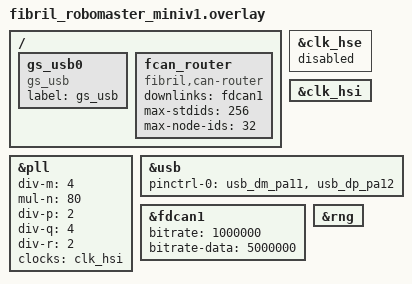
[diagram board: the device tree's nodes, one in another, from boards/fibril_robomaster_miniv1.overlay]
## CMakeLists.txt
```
# SPDX-License-Identifier: Apache-2.0
#
# Zephyr sample: fibril_can router + self node driven over CANnectivity's gs_usb
# uplink. Codegen produces the schema wrappers at build time from
# fibril_can_example/schema/example_node.yaml (same schema as example_node so
# the C service handlers and app_logic can be shared verbatim).
#
# Prerequisites: see the fibril_can module's zephyr/cmake/fcan_invoke_codegen.cmake
# for the fcan_codegen CLI resolution, and the message it prints if the binary
# is not on PATH.

cmake_minimum_required(VERSION 3.20.0)
find_package(Zephyr REQUIRED HINTS $ENV{ZEPHYR_BASE})

project(fibril_can_router_gs_usb_self LANGUAGES C)

if(NOT ZEPHYR_FIBRIL_CAN_MODULE_DIR)
  message(FATAL_ERROR
    "ZEPHYR_FIBRIL_CAN_MODULE_DIR is not set — is the fibril_can module on "
    "the west manifest and is CONFIG_FIBRIL_CAN=y?")
endif()

include(${ZEPHYR_FIBRIL_CAN_MODULE_DIR}/zephyr/cmake/fcan_invoke_codegen.cmake)

set(FCAN_EXAMPLE_SCHEMA
  "${ZEPHYR_FIBRIL_CAN_MODULE_DIR}/fibril_can_example/schema/example_node.yaml"
  CACHE FILEPATH "Schema YAML to feed into fcan_codegen")

fcan_invoke_codegen(
  SCHEMA     "${FCAN_EXAMPLE_SCHEMA}"
  OUTPUT_DIR "${CMAKE_CURRENT_BINARY_DIR}/schema_gen"
  BASE_NAME  schema_gen)

target_sources(app PRIVATE
  src/main.c
  src/app_logic.c
  src/rgb_state.c
  src/usbd_setup.c)

target_include_directories(app PRIVATE
  ${CMAKE_CURRENT_SOURCE_DIR}/src)
```

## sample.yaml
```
sample:
  name: fibril_can router + self node via CANnectivity gs_usb uplink
  description: >-
    Bring up a fibril_can slave whose typed wrappers are generated at build
    time by fcan_codegen from the shared example schema, embed it as the
    router's self node, and expose the router to a USB host through
    CANnectivity's gs_usb device class. A host on SocketCAN (or fibril_can_web
    over WebUSB) sees the self node's traffic combined with anything on the
    fdcan1 downlink through a single canX interface.

tests:
  sample.lib.fibril_can.router_gs_usb_self:
    tags:
      - fibril_can
      - can
      - router
      - usb
    # CONFIG_FIBRIL_CAN gates on the fibril_can module being on the west
    # manifest; the two dt_compat_enabled clauses gate on the board actually
    # wiring up both the router and a gs_usb node.
    filter: CONFIG_FIBRIL_CAN and dt_compat_enabled("fibril,can-router") and dt_compat_enabled("gs_usb")
    harness: console
    harness_config:
      type: multi_line
      ordered: true
      regex:
        - "router_gs_usb_self: fcan_init OK"
        - "router_gs_usb_self: fcan_router_attach_self OK"
        - "router_gs_usb_self: fcan_register_all OK"
        - "router_gs_usb_self: gs_usb_register OK"
        - "router_gs_usb_self: usbd_enable OK"
        - "router_gs_usb_self: entering main loop"
    integration_platforms:
      - fibril_robomaster_miniv1
    # Twister needs to know where fcan_codegen lives before it can build this
    # sample. Set FCAN_CODEGEN in the environment before invoking twister:
    #   FCAN_CODEGEN=/abs/path/fcan_codegen twister -T fibril_zephyr/samples/lib/fibril_can/router_gs_usb_self
    # or pass --extra-args=-DFCAN_CODEGEN=... to twister directly.
```

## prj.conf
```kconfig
# SPDX-License-Identifier: Apache-2.0

# --- fibril_can slave runtime + router driver
CONFIG_FIBRIL_CAN=y
CONFIG_CAN=y
CONFIG_CAN_FD_MODE=y
CONFIG_CAN_FCAN_ROUTER=y

# --- event-driven scheduler wake for fcan_zephyr_can_hal. This sample drives
#     fcan_poll(self) through the router thread (no fcan_zephyr_can_hal
#     instance), so the option has no runtime effect here; kept aligned with
#     the other fibril_can samples so the switch is uniform across the tree.
CONFIG_FCAN_ZEPHYR_EVENT_WAKE=y

# --- entropy for boot_id (used as ID-conflict tiebreaker + T_listen jitter
#     seed). Mini V1 has the on-chip RNG; overlay enables it.
CONFIG_ENTROPY_GENERATOR=y

# --- runtime allocation. K_HEAP_DEFINE in main.c carves its own arena, but
#     leave a small system heap for the CAN / USB / RNG drivers.
CONFIG_HEAP_MEM_POOL_SIZE=4096
CONFIG_MAIN_STACK_SIZE=4096

# --- USB device stack next + CANnectivity's gs_usb class. CONFIG_USBD_GS_USB
#     defaults to y whenever a "gs_usb" DT node is enabled, but state it
#     explicitly so the sample's intent is grep-able.
CONFIG_USB_DEVICE_STACK_NEXT=y
CONFIG_USBD_GS_USB=y

# Quieter USB stack -- switch the two lines below to _DBG when debugging USB
# enumeration failures on real hardware.
CONFIG_UDC_DRIVER_LOG_LEVEL_WRN=y
CONFIG_USBD_LOG_LEVEL_WRN=y
CONFIG_USBD_GS_USB_LOG_LEVEL_INF=y

# --- logging
CONFIG_LOG=y
CONFIG_LOG_MODE_IMMEDIATE=y
CONFIG_BOOT_BANNER=y
```

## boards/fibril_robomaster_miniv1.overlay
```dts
/*
 * SPDX-License-Identifier: Apache-2.0
 *
 * router+self+gs_usb sample on the Fibril RoboMaster Mini V1.
 *   uplink   = USB FS (PA11/PA12) -> gs_usb subsys -> fcan_router device
 *   downlink = FDCAN1 (PD0/PD1)   (board DTS already sets pinctrl + PLL_Q clock)
 *
 * The board's HSI48 + CLK48_SEL(0) supply the USB 48 MHz clock. This overlay
 * moves the PLL source from HSE (board DTS default) to HSI16 so the sample
 * boots on units where the 24 MHz HSE crystal is dead or unfitted -- the
 * Zephyr STM32 clock driver spin-waits for HSE ready and would hang boot
 * otherwise. HSI is ~1% accurate which is borderline for 5 Mbps FD data,
 * but adequate for bring-up. Switch back to HSE for production timing.
 */

/ {
	gs_usb0: gs_usb0 {
		compatible = "gs_usb";
		label = "gs_usb";
	};

	fcan_router: fcan_router {
		compatible = "fibril,can-router";
		status = "okay";
		downlinks = <&fdcan1>;
		max-stdids = <256>;
		max-node-ids = <32>;
	};
};

/* --- Clock tree: force HSI16 -> PLL, same VCO/SYSCLK/PLL_Q targets as the
 *     board's HSE path (VCO 320 MHz, SYSCLK 160 MHz, PLL_Q 80 MHz).
 *     HSI16 / div-m=4 = 4 MHz VCO input; * mul-n=80 = 320 MHz VCO;
 *     div-r=2 = 160 MHz SYSCLK; div-q=4 = 80 MHz PLL_Q. */
&clk_hse {
	status = "disabled";
};

&clk_hsi {
	status = "okay";
};

&pll {
	div-m = <4>;
	mul-n = <80>;
	div-p = <2>;
	div-q = <4>;
	div-r = <2>;
	clocks = <&clk_hsi>;
	status = "okay";
};

zephyr_udc0: &usb {
	pinctrl-0 = <&usb_dm_pa11 &usb_dp_pa12>;
	pinctrl-names = "default";
	status = "okay";
};

&fdcan1 {
	/* 1 Mbps arbitration / 5 Mbps FD data phase. PLL_Q kernel clock is 80 MHz
	 * per the board DTS -- 80 tq @ 1 Mbps, 16 tq @ 5 Mbps. */
	bitrate = <1000000>;
	bitrate-data = <5000000>;
	status = "okay";
};

&rng {
	status = "okay";
};
```

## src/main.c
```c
/*
 * SPDX-License-Identifier: Apache-2.0
 *
 * Zephyr entry point for the fibril_can router + self node + gs_usb sample.
 *
 * What the sample proves
 * ----------------------
 * 1. fcan_codegen'd wrappers link against the runtime on the Zephyr target.
 * 2. fcan_router (as a "fibril,can-router" Zephyr CAN device) hosts an
 *    embedded self node using fcan_router_get_self_hal()/
 *    fcan_router_attach_self() -- the three-step sequence documented in
 *    fibril_can/docs/09-router.md.
 * 3. The router device is registered as a gs_usb channel, so a host on USB
 *    sees a single CAN line that transparently combines the self node's
 *    traffic with any slaves attached to the fdcan1 downlink.
 * 4. fcan_router_poll() runs on the router driver thread and drives
 *    fcan_poll(self) internally, so the app main loop only has to publish
 *    telemetry and observe diagnostics.
 *
 * What the sample does NOT prove
 * ------------------------------
 * - Round-trip provisioning against fibril_can_bridge or fibril_can_web
 *   (needs a host process; see the README for the manual bring-up steps).
 * - Hardware timing on downlinks beyond what fdcan1's 1M/5M bitrate exercises
 *   in isolation.
 */

#include <stdint.h>
#include <string.h>

#include <zephyr/device.h>
#include <zephyr/drivers/can.h>
#include <zephyr/kernel.h>
#include <zephyr/logging/log.h>
#include <zephyr/random/random.h>

#include <cannectivity/usb/class/gs_usb.h>

#include <fibril_can/fcan.h>
#include <fibril_can/fcan_protocol.h>
#include <fibril_can/router/fcan_router.h>
#include <fibril_can_zephyr/can_router.h>

#include "schema_gen.h"
#include "app_logic.h"
#include "rgb_state.h"
#include "usbd_setup.h"

/* The C emitter puts these symbols in schema_blob.c but doesn't declare them
 * in schema_gen.h -- the C example does the same manual extern block. */
extern const uint8_t  fcan_schema_blob[];
extern const size_t   fcan_schema_blob_len;
extern const uint64_t fcan_schema_hash;

LOG_MODULE_REGISTER(router_gs_usb_self, LOG_LEVEL_INF);

#define ROUTER_NODE    DT_NODELABEL(fcan_router)
#define ROUTER_DEV     DEVICE_DT_GET(ROUTER_NODE)

/* Default 0x10 matches the fibril_can example schema's assumed slave ID; the
 * host bridge picks this up during ANNOUNCE. Override at build time with
 * -DCONFIG_EXTRA_CFLAGS=-DNODE_ID=0x?? if you need to run more than one of
 * these boards on the same bus. */
#ifndef NODE_ID
#define NODE_ID        0x10
#endif
#define MASTER_LOST_US 300000U  /* SPEC §5.11 -- 300 ms watchdog */

/* fcan_init calls the allocator once to carve every variable-length buffer
 * the runtime needs. Same 16 KiB budget as the example_node sample; the extra
 * headroom absorbs future schema growth without a re-tune. */
K_HEAP_DEFINE(fcan_heap, 16 * 1024);

static void *heap_alloc(size_t size, size_t align, void *ctx)
{
	ARG_UNUSED(ctx);
	return k_heap_aligned_alloc(&fcan_heap, align, size, K_NO_WAIT);
}

static const char *state_str(fcan_node_state_t s)
{
	switch (s) {
	case FCAN_STATE_UNPROVISIONED: return "UNPROVISIONED";
	case FCAN_STATE_PROVISIONED:   return "PROVISIONED";
	case FCAN_STATE_RUNNING:       return "RUNNING";
	case FCAN_STATE_FAULT:         return "FAULT";
	default:                       return "?";
	}
}

int main(void)
{
	const struct device *router = ROUTER_DEV;
	const struct device *gs_usb = DEVICE_DT_GET(DT_NODELABEL(gs_usb0));

	if (!device_is_ready(router)) {
		LOG_ERR("router device %s not ready", router->name);
		return -ENODEV;
	}

	fcan_router_t *r = fcan_router_zephyr_get(router);
	if (r == NULL) {
		LOG_ERR("fcan_router_zephyr_get returned NULL (router init failed)");
		return -ENODEV;
	}

	/* fcan_node_storage_size() is a runtime function (returns
	 * sizeof(fcan_node_t) -- opaque on purpose), so we heap-allocate the
	 * node instead of trying to size a static array. 8-byte alignment
	 * satisfies the seqlock and u64-hash fields the runtime keeps inside. */
	fcan_node_t *self = k_heap_aligned_alloc(&fcan_heap, 8,
						 fcan_node_storage_size(),
						 K_NO_WAIT);
	if (self == NULL) {
		LOG_ERR("fcan_heap OOM allocating node (%u bytes)",
			(unsigned)fcan_node_storage_size());
		return -ENOMEM;
	}

	/* MotorDriver has max_count=4 in the schema; ship 1 instance to keep
	 * the RAM footprint small. Imu is fixed count=1. */
	static const uint8_t counts[] = {1U, 1U};
	BUILD_ASSERT(ARRAY_SIZE(counts) == FCAN_NUM_BLOCK_ARRAYS,
		     "counts[] must match the schema's block-array count");

	fcan_config_t cfg = {
		.node_id = NODE_ID,
		.boot_id = sys_rand32_get(),
		.schema_blob = fcan_schema_blob,
		.schema_blob_len = (uint16_t)fcan_schema_blob_len,
		.schema_hash = fcan_schema_hash,
		.protocol_version = FCAN_PROTOCOL_VERSION,
		.block_count = FCAN_NUM_BLOCK_ARRAYS,
		.instance_counts = counts,
		.limits = {
			.max_frames = FCAN_MAX_FRAMES,
			.max_copy_entries = FCAN_MAX_COPY_ENTRIES,
			.service_buffer = FCAN_SERVICE_BUFFER,
			.service_reassembly = FCAN_SERVICE_REASSEMBLY,
			/* capacity fields filled below */
		},
		/* HAL comes from the router, not from a can_hal wrapper around
		 * a physical Zephyr CAN device: the router internally proxies
		 * this HAL onto its uplink, and the router thread drives
		 * fcan_poll(self) via fcan_router_poll(). */
		.hal = fcan_router_get_self_hal(r),
		.allocator = {.alloc = heap_alloc, .ctx = NULL},
		.master_lost_us = MASTER_LOST_US,
		/* .t_listen_us = 0 -> runtime picks the safe default. */
	};
	fcan_apply_schema_capacities(&cfg.limits, counts);

	if (fcan_init(self, &cfg) != FCAN_OK) {
		LOG_ERR("fcan_init failed (fault=%d)", (int)fcan_fault(self));
		return -EIO;
	}
	LOG_INF("fcan_init OK: node_id=0x%02x schema_hash=0x%016llx blob_len=%u",
		cfg.node_id, (unsigned long long)fcan_schema_hash,
		(unsigned)fcan_schema_blob_len);

	/* Attach BEFORE the router device is started (i.e. before the host can
	 * open the gs_usb channel). fcan_router_attach_self mutates state the
	 * router thread reads; docs/09-router.md documents this ordering. */
	if (fcan_router_attach_self(r, self) != FCAN_OK) {
		LOG_ERR("fcan_router_attach_self failed (fault=%d)",
			(int)fcan_fault(self));
		return -EIO;
	}
	LOG_INF("fcan_router_attach_self OK");

	if (fcan_register_all(self) != FCAN_OK) {
		LOG_ERR("fcan_register_all failed (fault=%d)",
			(int)fcan_fault(self));
		return -EIO;
	}
	LOG_INF("fcan_register_all OK");

	app_logic_init();
	rgb_state_init();

	if (!device_is_ready(gs_usb)) {
		LOG_ERR("gs_usb device %s not ready", gs_usb->name);
		return -ENODEV;
	}

	int rc = usbd_setup_init();
	if (rc != 0) {
		LOG_ERR("usbd_setup_init failed (%d)", rc);
		return rc;
	}

	const struct device *channels[] = {router};
	rc = gs_usb_register(gs_usb, channels, ARRAY_SIZE(channels), NULL, NULL);
	if (rc != 0) {
		LOG_ERR("gs_usb_register failed (%d)", rc);
		return rc;
	}
	LOG_INF("gs_usb_register OK (1 channel: %s)", router->name);

	rc = usbd_setup_enable();
	if (rc != 0) {
		return rc;
	}
	LOG_INF("usbd_enable OK");

	LOG_INF("entering main loop (tick=1 ms, state=%s)",
		state_str(fcan_state(self)));

	fcan_node_state_t last_state = fcan_state(self);
	uint32_t last_log_ms = 0;
	uint32_t last_led_ms = 0;
	while (true) {
		/* Threading model: fcan_poll(self) runs on the router driver
		 * thread (fcan_router_poll drives it at the end of each pass),
		 * so this main-thread app_logic_tick() must only use fcan APIs
		 * that are documented cross-thread-safe -- topic begin/commit/
		 * read and param_read are seqlock-protected per fcan_seqlock.h.
		 * Do NOT call fcan_svc_complete from here: it races the router
		 * thread's fcan_service_poll on the reassembly slots.
		 * app_logic.c completes the `home` service synchronously to
		 * keep that invariant, at the cost of skipping the ACCEPTED
		 * demo the example_node sample carries. */
		app_logic_tick(0.001f);

		const fcan_node_state_t s = fcan_state(self);
		if (s != last_state) {
			LOG_INF("state: %s -> %s (fault=%d)",
				state_str(last_state), state_str(s),
				(int)fcan_fault(self));
			last_state = s;
		}

		/* LED indicator @ ~100 Hz. GPIO toggles at every 1 ms tick would
		 * be wasteful; the blink phase is derived from k_uptime so a
		 * coarser refresh does not slur the animation. */
		const uint32_t now_ms = k_uptime_get_32();
		if ((now_ms - last_led_ms) >= 10U) {
			rgb_state_update(s, fcan_fault(self));
			last_led_ms = now_ms;
		}

		/* Router-oriented heartbeat log. fcan_router_get_diag() covers
		 * both forwarding directions and every drop reason; we surface
		 * the summary counters the operator needs to spot an
		 * ingress-drop condition or a runaway downlink. */
		if ((now_ms - last_log_ms) >= 1000U) {
			fcan_router_diag_t d;
			fcan_router_get_diag(r, &d);
			uint32_t ing_drops = fcan_router_zephyr_ingress_drops(router);
			LOG_INF("alive: state=%s up->dn[0]=%u dn->up[0]=%u "
				"drop_send=%u ingress_drops=%u",
				state_str(s),
				d.fwd_up_to_down[0], d.fwd_down_to_up[0],
				d.drop_send_failed, ing_drops);
			last_log_ms = now_ms;
		}

		k_msleep(1);
	}
	/* unreachable */
}
```

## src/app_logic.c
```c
/*
 * SPDX-License-Identifier: Apache-2.0
 *
 * Minimal toy application on top of the codegen wrappers. One MotorDriver
 * instance (motor0) integrates a 1-D dynamics model driven by the last M2S
 * `command` frame, publishes S2M `state` every tick and `diagnostics` at
 * ~10 Hz. One IMU instance publishes constant gyro/accel samples so the
 * S2M path is exercised for both block types.
 *
 * Divergence from example_node/src/app_logic.c
 * --------------------------------------------
 * Unlike example_node -- which runs fcan_poll and app_logic_tick on the same
 * main thread -- the router+self topology puts fcan_poll(self) on the router
 * driver thread (via fcan_router_poll) while app_logic_tick() runs on main.
 * Topic begin/commit/read and param_read stay safe across that boundary via
 * fcan_seqlock.h. fcan_svc_complete() does NOT: it races the router thread's
 * fcan_service_poll on the reassembly slots. So the `home` service handler
 * completes synchronously here (returns FCAN_SVC_OK with a filled response)
 * instead of stashing a handle for a later motordriver_home_complete call.
 * The deferred-response path is still demonstrated by the example_node sample.
 */

#include "app_logic.h"

#include <stdbool.h>
#include <stdint.h>

#include <zephyr/logging/log.h>

#include <fibril_can/fcan.h>
#include <fibril_can/fcan_protocol.h>

#include "schema_gen.h"

LOG_MODULE_REGISTER(fcan_app, LOG_LEVEL_INF);

#define MOTOR_INST      0U
#define IMU_INST        0U
#define DIAG_DIVIDER    100U  /* diagnostics @ 10 Hz when tick=1 kHz */

struct axis_state {
	float velocity;
	float position;
	float last_setpoint;
	uint8_t latched_mode;
	uint32_t fault_code;
	bool braked;
	uint32_t uptime_ticks;
};

static struct axis_state g_axis;

void app_logic_init(void)
{
	g_axis = (struct axis_state){0};
}

void app_logic_tick(float dt_seconds)
{
	/* 1. Absorb any queued master commands. */
	motordriver_command_t cmd;
	if (motordriver_command_read(MOTOR_INST, &cmd)) {
		g_axis.last_setpoint = cmd.setpoint;
		g_axis.latched_mode = cmd.mode;
	}
	motordriver_brake_t brk;
	if (motordriver_brake_read(MOTOR_INST, &brk)) {
		g_axis.braked = brk.engaged;
	}

	/* 2. Toy dynamics. Params are master-owned; we only read them. */
	const float kp = motordriver_param_kp(MOTOR_INST);
	const float torque_constant = motordriver_param_torque_constant(MOTOR_INST);
	const float drive = g_axis.braked ? 0.0f : kp * g_axis.last_setpoint;
	g_axis.velocity += drive * dt_seconds;
	g_axis.position += g_axis.velocity * dt_seconds;

	/* 3. High-rate telemetry. */
	motordriver_state_t *state = motordriver_state_begin(MOTOR_INST);
	if (state != NULL) {
		state->velocity = g_axis.velocity;
		state->position = g_axis.position;
		state->current = (torque_constant > 0.0f) ? drive / torque_constant : 0.0f;
		state->torque = drive;
		state->output_voltage = drive;
		state->bus_voltage = 24.0f;
		state->temperature = 25.0f;
		state->error_flags = g_axis.fault_code;
		motordriver_state_commit(MOTOR_INST);
	}

	/* 4. Low-rate diagnostics. No deferred-response completion here (see the
	 *    file header): motordriver_home returns synchronously in this sample
	 *    so nothing needs to complete a stashed handle from the app thread. */
	g_axis.uptime_ticks++;
	if ((g_axis.uptime_ticks % DIAG_DIVIDER) == 0U) {
		motordriver_diagnostics_t *diag = motordriver_diagnostics_begin(MOTOR_INST);
		if (diag != NULL) {
			diag->fault_code = g_axis.fault_code;
			diag->uptime_s = (uint32_t)((float)g_axis.uptime_ticks * dt_seconds);
			diag->mcu_temperature = 30.0f;
			diag->mode = g_axis.latched_mode;
			motordriver_diagnostics_commit(MOTOR_INST);
		}
	}

	/* 5. Constant IMU sample so the Imu S2M path is not dead code. */
	imu_sample_t *imu = imu_sample_begin(IMU_INST);
	if (imu != NULL) {
		imu->gyro[0] = 0.0f;
		imu->gyro[1] = 0.0f;
		imu->gyro[2] = 0.0f;
		imu->accel[0] = 0.0f;
		imu->accel[1] = 0.0f;
		imu->accel[2] = 9.81f;
		imu_sample_commit(IMU_INST);
	}
}

/* ---- Service handlers. codegen emits a dispatcher that calls each of these
 *      by symbol; any omission is a hard link error. See
 *      fibril_can_example/src/app_logic.cpp for the reference implementations. */

fcan_svc_status_t motordriver_set_mode(uint8_t inst,
				       const motordriver_set_mode_req_t *req,
				       motordriver_set_mode_resp_t *resp,
				       fcan_call_handle_t h)
{
	ARG_UNUSED(h);
	if (inst == MOTOR_INST) {
		g_axis.latched_mode = req->mode;
	}
	resp->accepted = true;
	return FCAN_SVC_OK;
}

fcan_svc_status_t motordriver_set_pid(uint8_t inst,
				      const motordriver_set_pid_req_t *req,
				      motordriver_set_pid_resp_t *resp,
				      fcan_call_handle_t h)
{
	ARG_UNUSED(inst);
	ARG_UNUSED(req);
	ARG_UNUSED(h);
	/* Canonical PID gain updates flow through PARAM_SET (§8). This handler
	 * exists so the schema's service surface is complete but does not
	 * touch the working values. */
	resp->accepted = true;
	return FCAN_SVC_OK;
}

fcan_svc_status_t motordriver_calibrate(uint8_t inst,
					const motordriver_calibrate_req_t *req,
					motordriver_calibrate_resp_t *resp,
					fcan_call_handle_t h)
{
	ARG_UNUSED(req);
	ARG_UNUSED(h);
	resp->offset = (inst == MOTOR_INST) ? g_axis.position : 0.0f;
	return FCAN_SVC_OK;
}

fcan_svc_status_t motordriver_clear_faults(uint8_t inst,
					   const motordriver_clear_faults_req_t *req,
					   motordriver_clear_faults_resp_t *resp,
					   fcan_call_handle_t h)
{
	ARG_UNUSED(req);
	ARG_UNUSED(h);
	if (inst == MOTOR_INST) {
		g_axis.fault_code = 0;
	}
	resp->success = true;
	return FCAN_SVC_OK;
}

fcan_svc_status_t motordriver_home(uint8_t inst,
				   const motordriver_home_req_t *req,
				   motordriver_home_resp_t *resp,
				   fcan_call_handle_t h)
{
	ARG_UNUSED(req);
	ARG_UNUSED(h);
	if (inst == MOTOR_INST) {
		g_axis.position = 0.0f;
		g_axis.velocity = 0.0f;
	}
	/* Synchronous completion: fill the response and return OK so the runtime
	 * sends it from this call's context (router driver thread). The
	 * deferred-response path (FCAN_SVC_ACCEPTED + motordriver_home_complete
	 * later) would trip on the router-thread vs app-thread race documented at
	 * the top of this file. */
	resp->success = true;
	return FCAN_SVC_OK;
}

void motordriver_on_params_changed(uint8_t inst, uint32_t changed_mask)
{
	LOG_INF("PARAM_SET applied: inst=%u mask=0x%08x kp=%f",
		inst, changed_mask, (double)motordriver_param_kp(inst));
}
```

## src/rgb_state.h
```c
/*
 * SPDX-License-Identifier: Apache-2.0
 *
 * Optional visual state indicator for the fibril_can example_node. Maps the
 * fcan_node runtime state (and fault code) onto the board's on-board LEDs so
 * a technician can see what the slave is doing without wiring up a serial
 * console.
 *
 * Boards that expose `led_r`, `led_g`, `led_b` gpio-leds children (currently:
 * fibril_robomaster_miniv1) drive the indicator. Boards that don't -- notably
 * native_sim -- fall back to a no-op implementation so the sample keeps
 * building unchanged.
 */

#ifndef FCAN_EXAMPLE_RGB_STATE_H_
#define FCAN_EXAMPLE_RGB_STATE_H_

#include <fibril_can/fcan_protocol.h>

#ifdef __cplusplus
extern "C" {
#endif

/* Configure the R/G/B outputs and drive them low (all off). Idempotent; safe
 * to call before the runtime is initialised. On boards without the three LED
 * nodes this is a no-op. */
void rgb_state_init(void);

/* Refresh the LED output for the given fcan runtime snapshot. Intended to be
 * called from the main loop at 100 Hz-ish; the internal blink phase is driven
 * from k_uptime_get_32() so callers do not need to keep any state.
 *
 * Priority: any non-NONE fault turns red on regardless of state. Otherwise:
 *   UNPROVISIONED -> blue, blinking at 1 Hz (500 ms on, 500 ms off)
 *   PROVISIONED   -> blue, solid
 *   RUNNING       -> green, solid
 *   FAULT         -> red, solid   (also reached via the fault-code branch)
 */
void rgb_state_update(fcan_node_state_t state, fcan_fault_t fault);

#ifdef __cplusplus
}
#endif

#endif /* FCAN_EXAMPLE_RGB_STATE_H_ */
```

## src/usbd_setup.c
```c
/*
 * SPDX-License-Identifier: Apache-2.0
 *
 * Minimal usbd_next boilerplate for the router+self+gs_usb sample.
 *
 * Compared to CANnectivity's app/src/usb.c this drops:
 *   - HS configuration      (Mini V1 is USB FS only)
 *   - DFU descriptors + switch-to-DFU flow
 *   - BOS + MSOSV2 platform capability (Windows WinUSB auto-bind)
 *
 * The registered class instance name matches gs_usb.c's USBD_DEFINE_CLASS
 * naming: the single "gs_usb" DT node lands at index 0 -> "gs_usb_0".
 */

#include "usbd_setup.h"

#include <zephyr/logging/log.h>
#include <zephyr/usb/usbd.h>

LOG_MODULE_REGISTER(usbd_setup, LOG_LEVEL_INF);

#define GS_USB_CLASS_INSTANCE_NAME "gs_usb_0"

/* Values match the CANnectivity firmware defaults so host-side udev rules and
 * gs_usb pid filters that already work with CANnectivity dongles work here
 * too. 0x1209 is pid.codes, 0xca01 is the block CANnectivity reserved for
 * gs_usb devices. Copy these values, don't include cannectivity's Kconfig --
 * that Kconfig only exists when its app is on the build. */
#define ROUTER_GS_USB_SELF_VID          0x1209U
#define ROUTER_GS_USB_SELF_PID          0xca01U
#define ROUTER_GS_USB_SELF_MANUFACTURER "CANnectivity"
#define ROUTER_GS_USB_SELF_PRODUCT      "CANnectivity USB to CAN adapter"
#define ROUTER_GS_USB_SELF_MAX_POWER    125U /* 250 mA (bMaxPower is in 2 mA units) */

USBD_DEVICE_DEFINE(usbd, DEVICE_DT_GET(DT_NODELABEL(zephyr_udc0)),
		   ROUTER_GS_USB_SELF_VID, ROUTER_GS_USB_SELF_PID);

USBD_DESC_LANG_DEFINE(lang);
USBD_DESC_MANUFACTURER_DEFINE(mfr, ROUTER_GS_USB_SELF_MANUFACTURER);
USBD_DESC_PRODUCT_DEFINE(product, ROUTER_GS_USB_SELF_PRODUCT);
USBD_DESC_SERIAL_NUMBER_DEFINE(sn);
USBD_DESC_CONFIG_DEFINE(fs_config_desc, "Full-Speed Configuration");

USBD_CONFIGURATION_DEFINE(fs_config, USB_SCD_SELF_POWERED,
			  ROUTER_GS_USB_SELF_MAX_POWER, &fs_config_desc);

int usbd_setup_init(void)
{
	int err;

	err = usbd_add_descriptor(&usbd, &lang);
	if (err != 0) {
		LOG_ERR("usbd_add_descriptor(lang) failed (%d)", err);
		return err;
	}

	err = usbd_add_descriptor(&usbd, &mfr);
	if (err != 0) {
		LOG_ERR("usbd_add_descriptor(mfr) failed (%d)", err);
		return err;
	}

	err = usbd_add_descriptor(&usbd, &product);
	if (err != 0) {
		LOG_ERR("usbd_add_descriptor(product) failed (%d)", err);
		return err;
	}

	err = usbd_add_descriptor(&usbd, &sn);
	if (err != 0) {
		LOG_ERR("usbd_add_descriptor(sn) failed (%d)", err);
		return err;
	}

	err = usbd_add_configuration(&usbd, USBD_SPEED_FS, &fs_config);
	if (err != 0) {
		LOG_ERR("usbd_add_configuration(fs) failed (%d)", err);
		return err;
	}

	err = usbd_register_class(&usbd, GS_USB_CLASS_INSTANCE_NAME,
				  USBD_SPEED_FS, 1);
	if (err != 0) {
		LOG_ERR("usbd_register_class(gs_usb_0) failed (%d)", err);
		return err;
	}

	err = usbd_device_set_code_triple(&usbd, USBD_SPEED_FS, 0, 0, 0);
	if (err != 0) {
		LOG_ERR("usbd_device_set_code_triple(fs) failed (%d)", err);
		return err;
	}

	err = usbd_device_set_bcd_usb(&usbd, USBD_SPEED_FS, USB_SRN_2_0_1);
	if (err != 0) {
		LOG_ERR("usbd_device_set_bcd_usb(fs) failed (%d)", err);
		return err;
	}

	err = usbd_init(&usbd);
	if (err != 0) {
		LOG_ERR("usbd_init failed (%d)", err);
		return err;
	}

	return 0;
}

int usbd_setup_enable(void)
{
	int err = usbd_enable(&usbd);

	if (err != 0) {
		LOG_ERR("usbd_enable failed (%d)", err);
	}
	return err;
}
```

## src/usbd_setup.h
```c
/*
 * SPDX-License-Identifier: Apache-2.0
 *
 * Minimal usbd_next boilerplate for the router+self+gs_usb sample. This is a
 * cut-down of CANnectivity's app/src/usb.c: full-speed only, no DFU, no
 * MSOSV2 descriptor set, no LED / termination / timestamp glue. The registered
 * gs_usb class instance ("gs_usb_0") is the same one CANnectivity registers.
 *
 * VID/PID/manufacturer/product strings are taken from the CANNECTIVITY_USB_*
 * Kconfig defaults so the resulting descriptor matches CANnectivity firmware.
 * That keeps existing host-side udev rules and gs_usb pid filters working.
 */

#ifndef ROUTER_GS_USB_SELF_USBD_SETUP_H_
#define ROUTER_GS_USB_SELF_USBD_SETUP_H_

#ifdef __cplusplus
extern "C" {
#endif

/* Register descriptors + full-speed configuration + the "gs_usb_0" class
 * instance, then call usbd_init(). Does NOT enable the device -- the caller
 * must first bind CAN channels via gs_usb_register() and only then call
 * usbd_setup_enable(). Returns 0 on success, a negative errno on failure. */
int usbd_setup_init(void);

/* Enable the previously-initialised USB device. Splitting this from init lets
 * the sample attach the router self node BEFORE the host can enumerate. */
int usbd_setup_enable(void);

#ifdef __cplusplus
}
#endif

#endif /* ROUTER_GS_USB_SELF_USBD_SETUP_H_ */
```
